# MK30D7 register map
File version: 1.6
Registers are 32-bit, read-write, reset 0x0 unless marked. A register's access mark holds for its fields unless they carry their own. Offsets are from the block's base; [hi:lo] are bit positions; {n}, {i} and the like mark numbered series; 'fields as' and 'values as' point back to an identical list.

## FTFL_FlashConfig — Flash Memory Interface
Base 0x00000400; register names take the prefix NV_
0x00 BACKKEY3 8-bit ro reset 0xFF — Backdoor Comparison Key 3.
  [7:0] KEY — Backdoor Comparison Key.
0x01 BACKKEY2 8-bit ro reset 0xFF — Backdoor Comparison Key 2.
  [7:0] KEY — Backdoor Comparison Key.
0x02 BACKKEY1 8-bit ro reset 0xFF — Backdoor Comparison Key 1.
  [7:0] KEY — Backdoor Comparison Key.
0x03 BACKKEY0 8-bit ro reset 0xFF — Backdoor Comparison Key 0.
  [7:0] KEY — Backdoor Comparison Key.
0x04 BACKKEY7 8-bit ro reset 0xFF — Backdoor Comparison Key 7.
  [7:0] KEY — Backdoor Comparison Key.
0x05 BACKKEY6 8-bit ro reset 0xFF — Backdoor Comparison Key 6.
  [7:0] KEY — Backdoor Comparison Key.
0x06 BACKKEY5 8-bit ro reset 0xFF — Backdoor Comparison Key 5.
  [7:0] KEY — Backdoor Comparison Key.
0x07 BACKKEY4 8-bit ro reset 0xFF — Backdoor Comparison Key 4.
  [7:0] KEY — Backdoor Comparison Key.
0x08 FPROT3 8-bit ro reset 0xFF — Non-volatile P-Flash Protection 1 - Low Register
  [7:0] PROT — P-Flash Region Protect
0x09 FPROT2 8-bit ro reset 0xFF — Non-volatile P-Flash Protection 1 - High Register
  [7:0] PROT — P-Flash Region Protect
0x0A FPROT1 8-bit ro reset 0xFF — Non-volatile P-Flash Protection 0 - Low Register
  [7:0] PROT — P-Flash Region Protect
0x0B FPROT0 8-bit ro reset 0xFF — Non-volatile P-Flash Protection 0 - High Register
  [7:0] PROT — P-Flash Region Protect
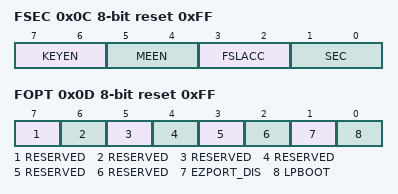
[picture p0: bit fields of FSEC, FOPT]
0x0C FSEC 8-bit ro reset 0xFF — Non-volatile Flash Security Register
  [7:6] KEYEN — Backdoor Key Security Enable
  [5:4] MEEN
  [3:2] FSLACC — Freescale Failure Analysis Access Code
  [1:0] SEC — Flash Security
0x0D FOPT 8-bit ro reset 0xFF — Non-volatile Flash Option Register
  [7] RESERVED, [6] RESERVED, [5] RESERVED, [4] RESERVED, [3] RESERVED, [2] RESERVED, [1] EZPORT_DIS, [0] LPBOOT
0x0E FEPROT 8-bit ro reset 0xFF — Non-volatile EERAM Protection Register
  [7:0] EPROT
0x0F FDPROT 8-bit ro reset 0xFF — Non-volatile D-Flash Protection Register
  [7:0] DPROT — D-Flash Region Protect

## AIPS0 — AIPS-Lite Bridge
Base 0x40000000; register names take the prefix AIPS0_
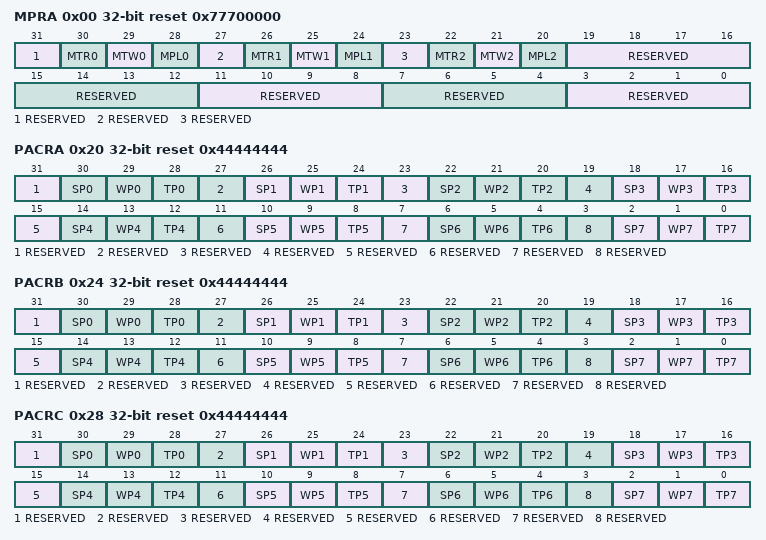
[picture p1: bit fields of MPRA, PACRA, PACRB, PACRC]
0x00 MPRA access per field reset 0x77700000 — Master Privilege Register A
  [31] RESERVED ro
  [30] MTR0 rw — Master trusted for read
    0=This master is not trusted for read accesses; 1=This master is trusted for read accesses
  [29] MTW0 rw — Master trusted for writes
    0=This master is not trusted for write accesses; 1=This master is trusted for write accesses
  [28] MPL0 rw — Master privilege level
    0=Accesses from this master are forced to user-mode; 1=Accesses from this master are not forced to user-mode
  [27] RESERVED ro
  [26] MTR1 rw — Master trusted for read
    values as MTR0
  [25] MTW1 rw — Master trusted for writes
    values as MTW0
  [24] MPL1 rw — Master privilege level
    values as MPL0
  [23] RESERVED ro
  [22] MTR2 rw — Master trusted for read
    values as MTR0
  [21] MTW2 rw — Master trusted for writes
    values as MTW0
  [20] MPL2 rw — Master privilege level
    values as MPL0
  [19:16] RESERVED ro
  [15:12] RESERVED ro
  [11:8] RESERVED ro
  [7:4] RESERVED ro
  [3:0] RESERVED ro
0x20 PACRA access per field reset 0x44444444 — Peripheral Access Control Register
  [31] RESERVED ro
  [30-4n] SP{n} rw (n=0..7) — Supervisor protect
    0=This peripheral does not require supervisor privilege level for accesses; 1=This peripheral requires supervisor privilege level for accesses
  [29-4n] WP{n} rw (n=0..7) — Write protect
    0=This peripheral allows write accesses; 1=This peripheral is write protected
  [28-4n] TP{n} rw (n=0..7) — Trusted protect
    0=Accesses from an untrusted master are allowed; 1=Accesses from an untrusted master are not allowed
  [27] RESERVED ro
  [23] RESERVED ro
  [19] RESERVED ro
  [15] RESERVED ro
  [11] RESERVED ro
  [7] RESERVED ro
  [3] RESERVED ro
0x24 PACRB access per field reset 0x44444444 — Peripheral Access Control Register
  fields as PACRA
0x28 PACRC access per field reset 0x44444444 — Peripheral Access Control Register
  fields as PACRA
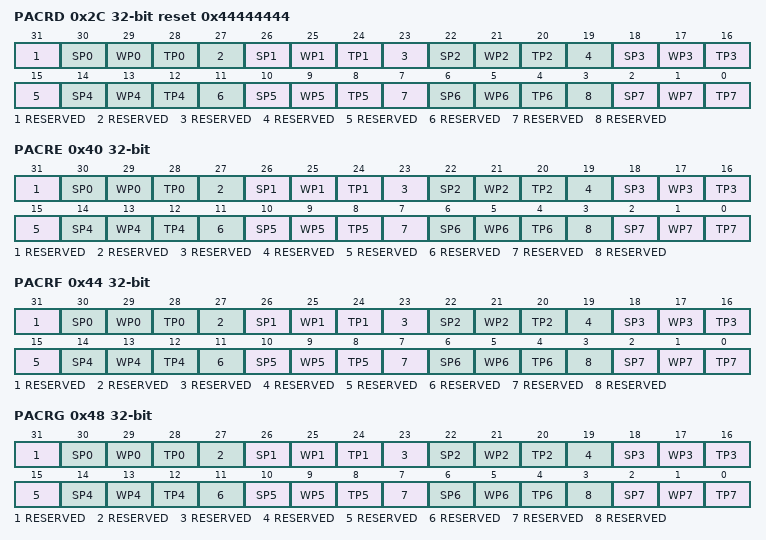
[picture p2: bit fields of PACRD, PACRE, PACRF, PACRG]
0x2C PACRD access per field reset 0x44444444 — Peripheral Access Control Register
  fields as PACRA
0x40 PACRE access per field reset not defined — Peripheral Access Control Register
  fields as PACRA
0x44 PACRF access per field reset not defined — Peripheral Access Control Register
  fields as PACRA
0x48 PACRG access per field reset not defined — Peripheral Access Control Register
  fields as PACRA
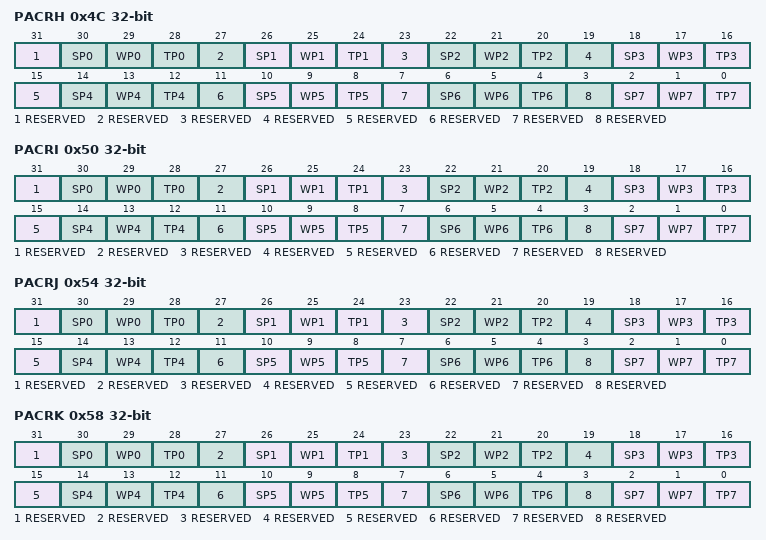
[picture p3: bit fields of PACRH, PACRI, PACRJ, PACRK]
0x4C PACRH access per field reset not defined — Peripheral Access Control Register
  fields as PACRA
0x50 PACRI access per field reset not defined — Peripheral Access Control Register
  fields as PACRA
0x54 PACRJ access per field reset not defined — Peripheral Access Control Register
  fields as PACRA
0x58 PACRK access per field reset not defined — Peripheral Access Control Register
  fields as PACRA
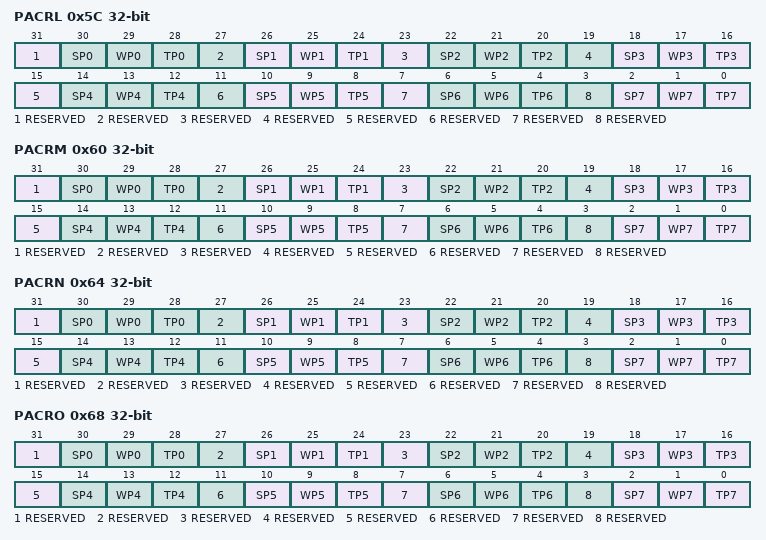
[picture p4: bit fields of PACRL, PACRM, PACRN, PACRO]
0x5C PACRL access per field reset not defined — Peripheral Access Control Register
  fields as PACRA
0x60 PACRM access per field reset not defined — Peripheral Access Control Register
  fields as PACRA
0x64 PACRN access per field reset not defined — Peripheral Access Control Register
  fields as PACRA
0x68 PACRO access per field reset not defined — Peripheral Access Control Register
  fields as PACRA
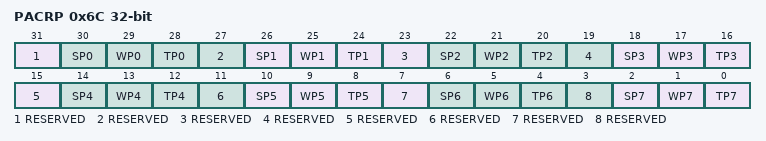
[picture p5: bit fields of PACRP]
0x6C PACRP access per field reset not defined — Peripheral Access Control Register
  fields as PACRA

## AIPS1 — AIPS-Lite Bridge
Base 0x40080000; register names take the prefix AIPS1_
Registers as AIPS0.
